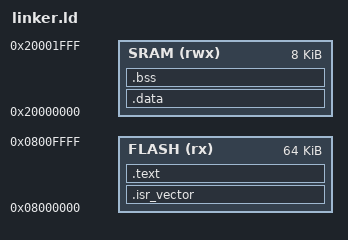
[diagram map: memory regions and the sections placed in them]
/*
 * FieldForge — ARM Cortex-M0 Linker Script
 * ==========================================
 * Target: STM32F030R8 (64KB Flash, 8KB SRAM) — representative Cortex-M0
 */

MEMORY
{
    FLASH (rx)  : ORIGIN = 0x08000000, LENGTH = 64K
    SRAM  (rwx) : ORIGIN = 0x20000000, LENGTH = 8K
}

_estack = ORIGIN(SRAM) + LENGTH(SRAM);

SECTIONS
{
    .isr_vector :
    {
        . = ALIGN(4);
        KEEP(*(.isr_vector))
        . = ALIGN(4);
    } > FLASH

    .text :
    {
        . = ALIGN(4);
        *(.text)
        *(.text*)
        *(.rodata)
        *(.rodata*)
        . = ALIGN(4);
        _etext = .;
    } > FLASH

    .data : AT(_etext)
    {
        . = ALIGN(4);
        _sdata = .;
        *(.data)
        *(.data*)
        . = ALIGN(4);
        _edata = .;
    } > SRAM

    .bss :
    {
        . = ALIGN(4);
        _sbss = .;
        *(.bss)
        *(.bss*)
        *(COMMON)
        . = ALIGN(4);
        _ebss = .;
    } > SRAM

    /DISCARD/ :
    {
        *(.ARM.attributes)
        *(.comment)
        *(.note*)
    }
}
